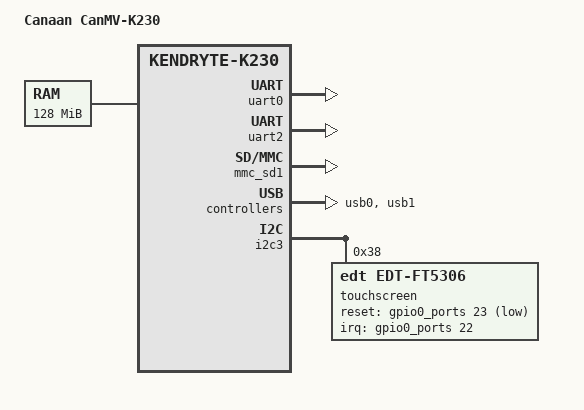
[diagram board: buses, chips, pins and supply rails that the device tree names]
// SPDX-License-Identifier: GPL-2.0 OR MIT
/*
 * Copyright (C) 2024 Yangyu Chen <cyy@cyyself.name>
 */

#include "k230.dtsi"
#include "display-st7701-480x800.dtsi"

/ {
	model = "Canaan CanMV-K230";
	compatible = "canaan,canmv-k230", "canaan,kendryte-k230";

	aliases {
		serial2 = &uart2;
		mmc0 = &mmc_sd1;
		mmc1 = &mmc_sd0;
	};

	chosen {
		stdout-path = "serial0:115200n8";
		bootargs = "root=/dev/mmcblk0p2 loglevel=8 rw rootdelay=4 \
						rootfstype=ext4 console=ttyS0,115200  earlycon=sbi";
	};

	ddr: memory@0 {
		device_type = "memory";
		reg = <0x0 0x0 0x0 0x8000000>;
	};

	sound {
		status                      = "okay";
		compatible                  = "canaan,k230-audio-inno";
		canaan,model                = "K230_I2S_INNO";
		canaan,k230-i2s-controller  = <&i2s>;
		canaan,k230-audio-codec     = <&inno_codec>;
	};
};

&uart0 {
	status = "okay";
};
&uart2 {
	status = "okay";
};
&mmc_sd1{
	status = "okay";
	no-1-8-v;
	cap-sd-highspeed;
	mshc_ctrl_r = <0x00>;
};
&usb0 {
	status = "okay";
};
&usb1 {
	status = "okay";
};

&i2c3 {
	status = "okay";
	touchscreen@38 {
		compatible = "edt,edt-ft5306";
		reg = <0x38>;
		reset-gpios = <&gpio0_ports 23 GPIO_ACTIVE_LOW>;
		interrupt-parent = <&gpio0_ports>;
		interrupts = <22 IRQ_TYPE_EDGE_FALLING>;
	};
};

&lcd {
	dsi_reset-gpios = <&gpio0_ports 24 GPIO_ACTIVE_HIGH>;
	backlight_gpio-gpios = <&gpio0_ports 25 GPIO_ACTIVE_HIGH>;
};
